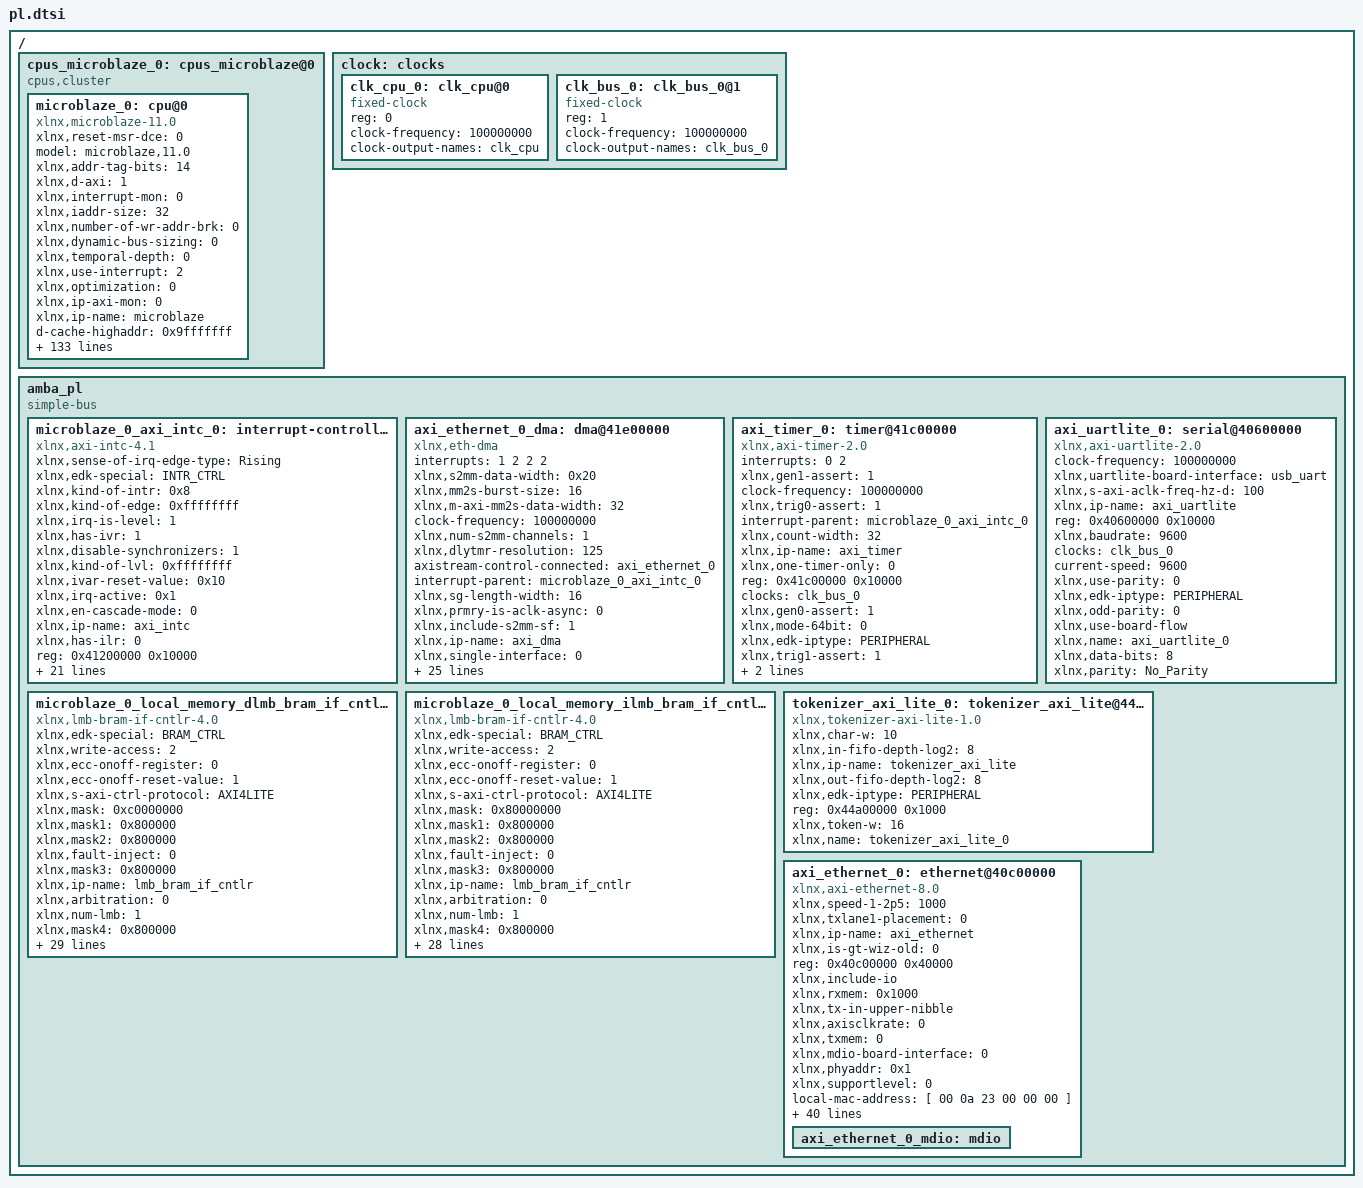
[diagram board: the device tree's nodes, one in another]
/ {
	cpus_microblaze_0: cpus_microblaze@0 {
		#cpu-mask-cells = <1>;
		compatible = "cpus,cluster";
		#address-cells = <1>;
		#size-cells = <0>;
		microblaze_0: cpu@0 {
			xlnx,reset-msr-dce = <0>;
			model = "microblaze,11.0";
			xlnx,addr-tag-bits = <14>;
			xlnx,d-axi = <1>;
			xlnx,interrupt-mon = <0>;
			xlnx,iaddr-size = <32>;
			xlnx,number-of-wr-addr-brk = <0>;
			xlnx,dynamic-bus-sizing = <0>;
			xlnx,temporal-depth = <0>;
			xlnx,use-interrupt = <2>;
			xlnx,optimization = <0>;
			xlnx,ip-axi-mon = <0>;
			xlnx,ip-name = "microblaze";
			d-cache-highaddr = <0x9fffffff>;
			xlnx,dcache-force-tag-lutram = <0>;
			xlnx,pc-width = <32>;
			xlnx,interrupt-is-edge = <0>;
			reg = <0x0>;
			xlnx,async-interrupt = <1>;
			xlnx,use-mmu = <0>;
			xlnx,reset-msr-ee = <0>;
			xlnx,icache-victims = <0>;
			xlnx,use-reorder-instr = <1>;
			xlnx,d-lmb-mon = <0>;
			xlnx,d-lmb-protocol = <0>;
			xlnx,ill-opcode-exception = <0>;
			xlnx,dcache-always-used = <1>;
			xlnx,use-div = <0>;
			xlnx,dc-axi-mon = <0>;
			xlnx,debug-trace-async-reset = <0>;
			xlnx,trace = <0>;
			xlnx,part = "xc7a200tsbg484-1";
			i-cache-baseaddr = <0x80000000>;
			xlnx,use-config-reset = <0>;
			xlnx,pvr = <0>;
			xlnx,i-lmb-mon = <0>;
			xlnx,dcache-byte-size = <32768>;
			xlnx,fault-tolerant = <0>;
			xlnx,family = "artix7";
			compatible = "xlnx,microblaze-11.0" , "xlnx,microblaze";
			xlnx,data-size = <32>;
			xlnx,mmu-zones = <16>;
			xlnx,debug-trace-size = <8192>;
			xlnx,mmu-privileged-instr = <0>;
			xlnx,enable-discrete-ports = <0>;
			d-cache-line-size = <16>;
			xlnx,d-lmb = <1>;
			xlnx,sco = <0>;
			xlnx,reset-msr-eip = <0>;
			xlnx,debug-interface = <0>;
			clock-frequency = <100000000>;
			xlnx,use-ext-brk = <0>;
			xlnx,daddr-size = <32>;
			xlnx,debug-enabled = <1>;
			xlnx,reset-msr-ice = <0>;
			xlnx,num-sync-ff-dbg-trace-clk = <2>;
			xlnx,i-lmb-protocol = <0>;
			xlnx,endianness = <1>;
			xlnx,fsl-exception = <0>;
			i-cache-line-size = <16>;
			xlnx,use-extended-fsl-instr = <0>;
			xlnx,reset-msr = <0x0>;
			xlnx,dp-axi-mon = <0>;
			device_type = "cpu";
			xlnx,branch-target-cache-size = <0>;
			xlnx,dcache-use-writeback = <0>;
			xlnx,div-zero-exception = <0>;
			xlnx,mmu-tlb-access = <3>;
			bus-handle = <&amba_pl>;
			xlnx,cache-byte-size = <32768>;
			xlnx,pvr-user2 = <0x0>;
			xlnx,opcode-0x0-illegal = <0>;
			xlnx,icache-line-len = <4>;
			xlnx,ecc-use-ce-exception = <0>;
			xlnx,base-vectors = <0x0>;
			xlnx,d-lmb-has-prot = <0>;
			xlnx,edk-special = "microblaze";
			xlnx,use-dcache = <1>;
			xlnx,use-barrel = <0>;
			xlnx,reset-msr-bip = <0>;
			xlnx,allow-dcache-wr = <1>;
			xlnx,debug-external-trace = <0>;
			xlnx,addr-size = <32>;
			xlnx,piaddr-size = <32>;
			i-cache-highaddr = <0x9fffffff>;
			xlnx,num-sync-ff-clk-debug = <2>;
			xlnx,debug-event-counters = <5>;
			xlnx,fpu-exception = <0>;
			xlnx,allow-icache-wr = <1>;
			xlnx,g-use-exceptions = <0>;
			xlnx,i-axi = <0>;
			xlnx,g-template-list = <0>;
			xlnx,icache-streams = <0>;
			xlnx,dcache-line-len = <4>;
			xlnx,num-sync-ff-clk = <2>;
			xlnx,edk-iptype = "PROCESSOR";
			xlnx,use-stack-protection = <0>;
			xlnx,use-hw-mul = <0>;
			xlnx,num-sync-ff-dbg-clk = <1>;
			xlnx,interconnect = <2>;
			xlnx,i-lmb-has-prot = <0>;
			xlnx,debug-latency-counters = <1>;
			i-cache-size = <32768>;
			xlnx,exceptions-in-delay-slots = <1>;
			xlnx,use-fpu = <0>;
			xlnx,reset-msr-ie = <0>;
			xlnx,edge-is-positive = <1>;
			xlnx,use-pcmp-instr = <0>;
			xlnx,use-icache = <1>;
			d-cache-size = <32768>;
			xlnx,memory-ip-list = "microblaze_0_local_memory_ilmb_bram_if_cntlr_memory" , "microblaze_0_local_memory_dlmb_bram_if_cntlr_memory" , "mig_7series_0_memory" , "mig_7series_0_memory";
			xlnx,async-wakeup = <3>;
			xlnx,use-non-secure = <0>;
			xlnx,dcache-addr-tag = <14>;
			xlnx,number-of-rd-addr-brk = <0>;
			d-cache-baseaddr = <0x80000000>;
			xlnx,area-optimized = <0>;
			xlnx,avoid-primitives = <0>;
			xlnx,lockstep-slave = <0>;
			xlnx,use-ext-nm-brk = <0>;
			xlnx,instr-size = <32>;
			interrupt-handle = <&microblaze_0_axi_intc_0>;
			xlnx,icache-always-used = <1>;
			xlnx,i-lmb = <1>;
			xlnx,mmu-dtlb-size = <4>;
			xlnx,lockstep-select = <0>;
			xlnx,lmb-data-size = <32>;
			xlnx,ic-axi-mon = <0>;
			xlnx,enable-conversion = <0>;
			xlnx,num-sync-ff-clk-irq = <1>;
			xlnx,fsl-links = <0>;
			timebase-frequency = <100000000>;
			xlnx,icache-force-tag-lutram = <0>;
			xlnx,dcache-data-width = <0>;
			xlnx,dcache-victims = <0>;
			xlnx,use-branch-target-cache = <0>;
			xlnx,debug-profile-size = <0>;
			xlnx,unaligned-exceptions = <0>;
			xlnx,lockstep-master = <0>;
			xlnx,freq = <100000000>;
			xlnx,number-of-pc-brk = <1>;
			xlnx,mmu-itlb-size = <2>;
			xlnx,imprecise-exceptions = <0>;
			xlnx,use-msr-instr = <0>;
			xlnx,icache-data-width = <0>;
			xlnx,debug-counter-width = <32>;
		};
	};
	clock: clocks {
		#address-cells = <1>;
		#size-cells = <0>;
		clk_cpu_0: clk_cpu@0 {
			compatible = "fixed-clock";
			reg = <0>;
			clock-frequency = <100000000>;
			clock-output-names = "clk_cpu";
			#clock-cells = <0>;
		};
		clk_bus_0: clk_bus_0@1 {
			compatible = "fixed-clock";
			reg = <1>;
			clock-frequency = <100000000>;
			clock-output-names = "clk_bus_0";
			#clock-cells = <0>;
		};
	};
	amba_pl: amba_pl {
		ranges;
		compatible = "simple-bus";
		#address-cells = <1>;
		#size-cells = <1>;
		microblaze_0_axi_intc_0: interrupt-controller@41200000 {
			#interrupt-cells = <2>;
			xlnx,sense-of-irq-edge-type = "Rising";
			xlnx,edk-special = "INTR_CTRL";
			xlnx,kind-of-intr = <0x8>;
			xlnx,kind-of-edge = <0xffffffff>;
			xlnx,irq-is-level = <1>;
			xlnx,has-ivr = <1>;
			compatible = "xlnx,axi-intc-4.1" , "xlnx,xps-intc-1.00.a";
			xlnx,disable-synchronizers = <1>;
			xlnx,kind-of-lvl = <0xffffffff>;
			xlnx,ivar-reset-value = <0x10>;
			xlnx,irq-active = <0x1>;
			xlnx,en-cascade-mode = <0>;
			xlnx,ip-name = "axi_intc";
			xlnx,has-ilr = <0>;
			reg = <0x41200000 0x10000>;
			xlnx,addr-width = <0x20>;
			xlnx,s-axi-aclk-freq-mhz = <100>;
			xlnx,num-sw-intr = <0>;
			xlnx,irq-connection = <0>;
			xlnx,num-intr-inputs = <0x5>;
			xlnx,has-sie = <1>;
			xlnx,enable-async = <0>;
			xlnx,has-cie = <1>;
			xlnx,num-sync-ff = <2>;
			xlnx,edk-iptype = "PERIPHERAL";
			xlnx,mb-clk-not-connected = <1>;
			xlnx,has-ipr = <1>;
			xlnx,sense-of-irq-level-type = "Active_High";
			xlnx,cascade-master = <0>;
			xlnx,processor-clk-freq-mhz = <100>;
			status = "okay";
			xlnx,is-fast = <0x1>;
			xlnx,has-fast = <1>;
			xlnx,ivar-rst-val = <0x10>;
			interrupt-controller;
			xlnx,async-intr = <0xfffffff8>;
			xlnx,name = "microblaze_0_axi_intc_0";
		};
		axi_ethernet_0_dma: dma@41e00000 {
			interrupts = < 1 2 2 2 >;
			compatible = "xlnx,eth-dma";
			xlnx,s2mm-data-width = <0x20>;
			xlnx,mm2s-burst-size = <16>;
			xlnx,m-axi-mm2s-data-width = <32>;
			clock-frequency = <100000000>;
			xlnx,num-s2mm-channels = <1>;
			xlnx,dlytmr-resolution = <125>;
			axistream-control-connected = <&axi_ethernet_0>;
			interrupt-parent = <&microblaze_0_axi_intc_0>;
			xlnx,sg-length-width = <16>;
			xlnx,prmry-is-aclk-async = <0>;
			xlnx,include-s2mm-sf = <1>;
			#dma-cells = <1>;
			xlnx,ip-name = "axi_dma";
			xlnx,single-interface = <0>;
			xlnx,sg-include-stscntrl-strm = <1>;
			xlnx,include-s2mm-dre = <1>;
			reg = <0x41e00000 0x10000>;
			xlnx,addr-width = <32>;
			xlnx,include-s2mm = <1>;
			clocks = <&clk_bus_0>;
			xlnx,s-axis-s2mm-tdata-width = <32>;
			xlnx,micro-dma = <0>;
			xlnx,increase-throughput = <0>;
			xlnx,mm2s-data-width = <0x20>;
			xlnx,addrwidth = <0x20>;
			xlnx,sg-use-stsapp-length = <1>;
			xlnx,m-axis-mm2s-tdata-width = <32>;
			xlnx,include-dre;
			xlnx,edk-iptype = "PERIPHERAL";
			xlnx,s2mm-burst-size = <16>;
			xlnx,m-axi-s2mm-data-width = <32>;
			xlnx,num-queues = /bits/ 16 <0x1>;
			xlnx,num-mm2s-channels = <1>;
			xlnx,enable-multi-channel = <0>;
			status = "okay";
			xlnx,include-mm2s-sf = <1>;
			clock-names = "s_axi_lite_aclk";
			axistream-connected = <&axi_ethernet_0>;
			interrupt-names = "mm2s_introut" , "s2mm_introut";
			xlnx,include-mm2s = <1>;
			xlnx,include-mm2s-dre = <1>;
			xlnx,name = "axi_ethernet_0_dma";
		};
		axi_timer_0: timer@41c00000 {
			interrupts = < 0 2 >;
			compatible = "xlnx,axi-timer-2.0" , "xlnx,xps-timer-1.00.a";
			xlnx,gen1-assert = <1>;
			clock-frequency = <100000000>;
			xlnx,trig0-assert = <1>;
			interrupt-parent = <&microblaze_0_axi_intc_0>;
			xlnx,count-width = <32>;
			xlnx,ip-name = "axi_timer";
			xlnx,one-timer-only = <0>;
			reg = <0x41c00000 0x10000>;
			clocks = <&clk_bus_0>;
			xlnx,gen0-assert = <1>;
			xlnx,mode-64bit = <0>;
			xlnx,edk-iptype = "PERIPHERAL";
			status = "okay";
			xlnx,trig1-assert = <1>;
			xlnx,enable-timer2 = <1>;
			interrupt-names = "interrupt";
			xlnx,name = "axi_timer_0";
		};
		axi_uartlite_0: serial@40600000 {
			compatible = "xlnx,axi-uartlite-2.0" , "xlnx,xps-uartlite-1.00.a";
			clock-frequency = <100000000>;
			xlnx,uartlite-board-interface = "usb_uart";
			xlnx,s-axi-aclk-freq-hz-d = <100>;
			xlnx,ip-name = "axi_uartlite";
			reg = <0x40600000 0x10000>;
			xlnx,baudrate = <9600>;
			clocks = <&clk_bus_0>;
			current-speed = <9600>;
			xlnx,use-parity = <0>;
			xlnx,edk-iptype = "PERIPHERAL";
			xlnx,odd-parity = <0>;
			status = "okay";
			xlnx,use-board-flow;
			xlnx,name = "axi_uartlite_0";
			xlnx,data-bits = <8>;
			xlnx,parity = "No_Parity";
		};
		microblaze_0_local_memory_dlmb_bram_if_cntlr: lmb_bram_if_cntlr@0 {
			xlnx,edk-special = "BRAM_CTRL";
			xlnx,write-access = <2>;
			compatible = "xlnx,lmb-bram-if-cntlr-4.0" , "xlnx,axi-bram-ctrl";
			xlnx,ecc-onoff-register = <0>;
			xlnx,ecc-onoff-reset-value = <1>;
			xlnx,s-axi-ctrl-protocol = "AXI4LITE";
			xlnx,mask = <0xc0000000>;
			xlnx,mask1 = <0x800000>;
			xlnx,mask2 = <0x800000>;
			xlnx,fault-inject = <0>;
			xlnx,mask3 = <0x800000>;
			xlnx,ip-name = "lmb_bram_if_cntlr";
			xlnx,arbitration = <0>;
			xlnx,num-lmb = <1>;
			xlnx,mask4 = <0x800000>;
			reg = <0x00000000 0x20000>;
			xlnx,s-axi-ctrl-addr-width = <32>;
			xlnx,mask5 = <0x800000>;
			xlnx,ecc-status-registers = <0>;
			xlnx,prot-cfg = <0xff>;
			xlnx,mask6 = <0x800000>;
			xlnx,lmb-protocol = <0>;
			xlnx,ce-counter-width = <0>;
			xlnx,prot-cfg1 = <0xff>;
			xlnx,mask7 = <0x800000>;
			xlnx,ecc = <0>;
			xlnx,edk-iptype = "PERIPHERAL";
			xlnx,prot-cfg2 = <0xff>;
			xlnx,lmb-dwidth = <32>;
			xlnx,interconnect = <0>;
			xlnx,ce-failing-registers = <0>;
			xlnx,prot-cfg3 = <0xff>;
			xlnx,ue-failing-registers = <0>;
			xlnx,prot-cfg4 = <0xff>;
			xlnx,lmb-has-prot = <0>;
			status = "okay";
			xlnx,data-width = <32>;
			xlnx,prot-cfg5 = <0xff>;
			xlnx,s-axi-ctrl-data-width = <32>;
			xlnx,prot-cfg6 = <0xff>;
			xlnx,bram-awidth = <32>;
			xlnx,prot-cfg7 = <0xff>;
			xlnx,lmb-awidth = <32>;
			xlnx,name = "microblaze_0_local_memory_dlmb_bram_if_cntlr";
		};
		microblaze_0_local_memory_ilmb_bram_if_cntlr: microblaze_0_local_memory_ilmb_bram_if_cntlr@0 {
			xlnx,edk-special = "BRAM_CTRL";
			xlnx,write-access = <2>;
			compatible = "xlnx,lmb-bram-if-cntlr-4.0" , "xlnx,axi-bram-ctrl";
			xlnx,ecc-onoff-register = <0>;
			xlnx,ecc-onoff-reset-value = <1>;
			xlnx,s-axi-ctrl-protocol = "AXI4LITE";
			xlnx,mask = <0x80000000>;
			xlnx,mask1 = <0x800000>;
			xlnx,mask2 = <0x800000>;
			xlnx,fault-inject = <0>;
			xlnx,mask3 = <0x800000>;
			xlnx,ip-name = "lmb_bram_if_cntlr";
			xlnx,arbitration = <0>;
			xlnx,num-lmb = <1>;
			xlnx,mask4 = <0x800000>;
			reg = <0x00000000 0x20000>;
			xlnx,s-axi-ctrl-addr-width = <32>;
			xlnx,mask5 = <0x800000>;
			xlnx,ecc-status-registers = <0>;
			xlnx,prot-cfg = <0xff>;
			xlnx,mask6 = <0x800000>;
			xlnx,lmb-protocol = <0>;
			xlnx,ce-counter-width = <0>;
			xlnx,prot-cfg1 = <0xff>;
			xlnx,mask7 = <0x800000>;
			xlnx,ecc = <0>;
			xlnx,edk-iptype = "PERIPHERAL";
			xlnx,prot-cfg2 = <0xff>;
			xlnx,lmb-dwidth = <32>;
			xlnx,interconnect = <0>;
			xlnx,ce-failing-registers = <0>;
			xlnx,prot-cfg3 = <0xff>;
			xlnx,ue-failing-registers = <0>;
			xlnx,prot-cfg4 = <0xff>;
			xlnx,lmb-has-prot = <0>;
			status = "okay";
			xlnx,prot-cfg5 = <0xff>;
			xlnx,s-axi-ctrl-data-width = <32>;
			xlnx,prot-cfg6 = <0xff>;
			xlnx,bram-awidth = <32>;
			xlnx,prot-cfg7 = <0xff>;
			xlnx,lmb-awidth = <32>;
			xlnx,name = "microblaze_0_local_memory_ilmb_bram_if_cntlr";
		};
		tokenizer_axi_lite_0: tokenizer_axi_lite@44a00000 {
			xlnx,char-w = <10>;
			compatible = "xlnx,tokenizer-axi-lite-1.0";
			status = "okay";
			xlnx,in-fifo-depth-log2 = <8>;
			xlnx,ip-name = "tokenizer_axi_lite";
			xlnx,out-fifo-depth-log2 = <8>;
			xlnx,edk-iptype = "PERIPHERAL";
			reg = <0x44a00000 0x1000>;
			xlnx,token-w = <16>;
			xlnx,name = "tokenizer_axi_lite_0";
		};
		axi_ethernet_0: ethernet@40c00000 {
			xlnx,speed-1-2p5 = <1000>;
			xlnx,txlane1-placement = "0";
			xlnx,ip-name = "axi_ethernet";
			xlnx,is-gt-wiz-old = <0>;
			reg = <0x40c00000 0x40000>;
			xlnx,include-io;
			xlnx,rxmem = <0x1000>;
			xlnx,tx-in-upper-nibble;
			xlnx,axisclkrate = <0>;
			xlnx,txmem = "0";
			xlnx,mdio-board-interface = "0";
			xlnx,phyaddr = <0x1>;
			xlnx,supportlevel = <0>;
			local-mac-address = [ 00 0a 23 00 00 00 ];
			xlnx,diffclk-board-interface = "0";
			xlnx,frame-filter;
			axistream-connected = <&axi_ethernet_0_dma>;
			xlnx,phyrst-board-interface-dummy-port = "0";
			interrupt-names = "interrupt" , "mac_irq" , "mm2s_introut" , "s2mm_introut";
			compatible = "xlnx,axi-ethernet-8.0" , "xlnx,axi-ethernet-1.00.a" , "xlnx,axi-ethernet-1.00.a";
			xlnx,gt-type = "0";
			xlnx,drpclkrate = <0>;
			clock-frequency = <>;
			axistream-control-connected = <&axi_ethernet_0_dma>;
			interrupt-parent = <&microblaze_0_axi_intc_0>;
			xlnx,versal-gt-board-flow = <0>;
			xlnx,num-queues = /bits/ 16 <0x1>;
			xlnx,channel-ids = < 1 >;
			max-speed = <1000>;
			status = "okay";
			xlnx,timer-format = <0>;
			xlnx,use-board-flow;
			xlnx,statistics-width = "0";
			xlnx,name = "axi_ethernet_0";
			interrupts = < 4 2 3 0 >;
			xlnx,gtrefclksrc = "0";
			xlnx,rxcsum = <0x0>;
			xlnx,statistics-counters;
			xlnx,include-dre;
			xlnx,edk-iptype = "0";
			xlnx,gtrefclkrate = <0>;
			xlnx,lvdsclkrate = <0>;
			xlnx,number-of-table-entries = <0>;
			xlnx,rxlane0-placement = "0";
			xlnx,timer-clk-period = <0>;
			xlnx,ethernet-board-interface = "0";
			xlnx,txlane0-placement = "0";
			xlnx,gtlocation = "0";
			phy-mode = "rgmii";
			xlnx,gt-settings = <0>;
			xlnx,clockselection = "0";
			xlnx,processor-mode;
			xlnx,txcsum = <0x0>;
			xlnx,phyrst-board-interface = "0";
			xlnx,axiliteclkrate = <0>;
			xlnx,rxlane1-placement = "0";
			axi_ethernet_0_mdio: mdio {
				#address-cells = <1>;
				#size-cells = <0>;
			};
		};
	};
};
